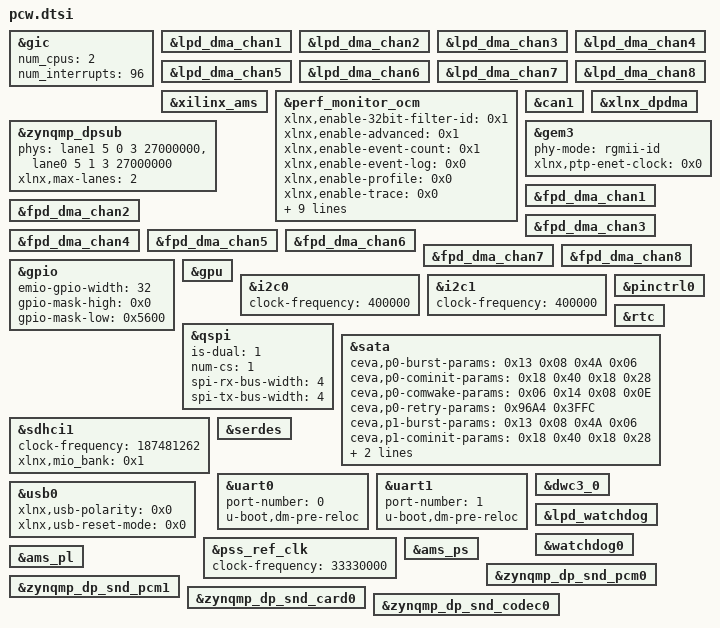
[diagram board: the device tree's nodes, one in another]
/*
 * CAUTION: This file is automatically generated by Xilinx.
 * Version:  
 * Today is: Tue Apr 17 04:37:55 2018
 */


&gic {
	num_cpus = <2>;
	num_interrupts = <96>;
};
&lpd_dma_chan1 {
	status = "okay";
};
&lpd_dma_chan2 {
	status = "okay";
};
&lpd_dma_chan3 {
	status = "okay";
};
&lpd_dma_chan4 {
	status = "okay";
};
&lpd_dma_chan5 {
	status = "okay";
};
&lpd_dma_chan6 {
	status = "okay";
};
&lpd_dma_chan7 {
	status = "okay";
};
&lpd_dma_chan8 {
	status = "okay";
};
&xilinx_ams {
	status = "okay";
};
&perf_monitor_ocm {
	xlnx,enable-32bit-filter-id = <0x1>;
	xlnx,enable-advanced = <0x1>;
	xlnx,enable-event-count = <0x1>;
	xlnx,enable-event-log = <0x0>;
	xlnx,enable-profile = <0x0>;
	xlnx,enable-trace = <0x0>;
	xlnx,fifo-axis-depth = <0x20>;
	xlnx,fifo-axis-tdata-width = <0x38>;
	xlnx,fifo-axis-tid-width = <0x1>;
	xlnx,global-count-width = <0x20>;
	xlnx,have-sampled-metric-cnt = <0x1>;
	xlnx,metric-count-scale = <0x1>;
	xlnx,metrics-sample-count-width = <0x20>;
	xlnx,num-monitor-slots = <0x1>;
	xlnx,num-of-counters = <0x3>;
};
&can1 {
	status = "okay";
};
&zynqmp_dpsub {
	phy-names = "dp-phy0","dp-phy1";
	phys = <&lane1 5 0 3 27000000>,
		<&lane0 5 1 3 27000000>;
	status = "okay";
	xlnx,max-lanes = <2>;
};
&xlnx_dpdma {
	status = "okay";
};
&gem3 {
	phy-mode = "rgmii-id";
	status = "okay";
	xlnx,ptp-enet-clock = <0x0>;
};
&fpd_dma_chan1 {
	status = "okay";
};
&fpd_dma_chan2 {
	status = "okay";
};
&fpd_dma_chan3 {
	status = "okay";
};
&fpd_dma_chan4 {
	status = "okay";
};
&fpd_dma_chan5 {
	status = "okay";
};
&fpd_dma_chan6 {
	status = "okay";
};
&fpd_dma_chan7 {
	status = "okay";
};
&fpd_dma_chan8 {
	status = "okay";
};
&gpio {
	emio-gpio-width = <32>;
	gpio-mask-high = <0x0>;
	gpio-mask-low = <0x5600>;
	status = "okay";
};
&gpu {
	status = "okay";
};
&i2c0 {
	clock-frequency = <400000>;
	status = "okay";
};
&i2c1 {
	clock-frequency = <400000>;
	status = "okay";
};
&pinctrl0 {
	status = "okay";
};
&qspi {
	is-dual = <1>;
	num-cs = <1>;
	spi-rx-bus-width = <4>;
	spi-tx-bus-width = <4>;
	status = "okay";
};
&rtc {
	status = "okay";
};
&sata {
	ceva,p0-burst-params = /bits/ 8 <0x13 0x08 0x4A 0x06>;
	ceva,p0-cominit-params = /bits/ 8 <0x18 0x40 0x18 0x28>;
	ceva,p0-comwake-params = /bits/ 8 <0x06 0x14 0x08 0x0E>;
	ceva,p0-retry-params = /bits/ 16 <0x96A4 0x3FFC>;
	ceva,p1-burst-params = /bits/ 8 <0x13 0x08 0x4A 0x06>;
	ceva,p1-cominit-params = /bits/ 8 <0x18 0x40 0x18 0x28>;
	ceva,p1-comwake-params = /bits/ 8 <0x06 0x14 0x08 0x0E>;
	ceva,p1-retry-params = /bits/ 16 <0x96A4 0x3FFC>;
	status = "okay";
};
&sdhci1 {
	clock-frequency = <187481262>;
	status = "okay";
	xlnx,mio_bank = <0x1>;
};
&serdes {
	status = "okay";
};
&uart0 {
	device_type = "serial";
	port-number = <0>;
	status = "okay";
	u-boot,dm-pre-reloc ;
};
&uart1 {
	device_type = "serial";
	port-number = <1>;
	status = "okay";
	u-boot,dm-pre-reloc ;
};
&usb0 {
	status = "okay";
	xlnx,usb-polarity = <0x0>;
	xlnx,usb-reset-mode = <0x0>;
};
&dwc3_0 {
	status = "okay";
};
&lpd_watchdog {
	status = "okay";
};
&watchdog0 {
	status = "okay";
};
&pss_ref_clk {
	clock-frequency = <33330000>;
};
&ams_ps {
	status = "okay";
};
&ams_pl {
	status = "okay";
};
&zynqmp_dp_snd_pcm0 {
	status = "okay";
};
&zynqmp_dp_snd_pcm1 {
	status = "okay";
};
&zynqmp_dp_snd_card0 {
	status = "okay";
};
&zynqmp_dp_snd_codec0 {
	status = "okay";
};
